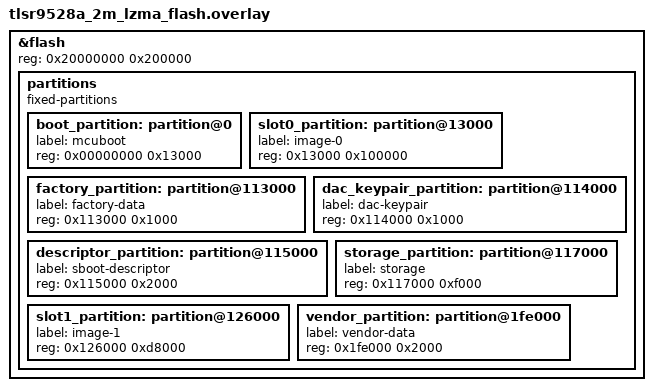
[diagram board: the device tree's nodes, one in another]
&flash {
	reg = <0x20000000 0x200000>;

	/delete-node/ partitions;
	partitions {
		compatible = "fixed-partitions";
		#address-cells = <1>;
		#size-cells = <1>;

		boot_partition: partition@0 {
			label = "mcuboot";
			reg = <0x00000000 0x13000>;
		};
		slot0_partition: partition@13000 {
			label = "image-0";
			reg = <0x13000 0x100000>;
		};
		factory_partition: partition@113000 {
			label = "factory-data";
			reg = <0x113000 0x1000>;
		};
		dac_keypair_partition: partition@114000 {
 			label = "dac-keypair";
			reg = <0x114000 0x1000>; //store dac and key pair.
 		};
		descriptor_partition: partition@115000 {
			label = "sboot-descriptor";
			reg = <0x115000 0x2000>;
		};
		storage_partition: partition@117000 {
			label = "storage";
			reg = <0x117000 0xf000>;
		};
		slot1_partition: partition@126000 {
			label = "image-1";
			reg = <0x126000 0xd8000>;
		};
		vendor_partition: partition@1fe000 {
			label = "vendor-data";
			reg = <0x1fe000 0x2000>;
		};
	};
};
